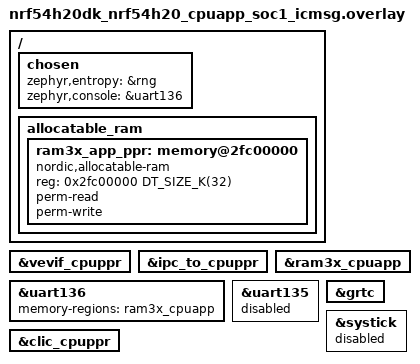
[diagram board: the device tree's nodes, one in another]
/*
 * Copyright (c) 2022 Nordic Semiconductor ASA
 *
 * SPDX-License-Identifier: LicenseRef-Nordic-5-Clause
 */

/ {
	chosen {
		zephyr,entropy = &rng;
		zephyr,console = &uart136;
	};

	allocatable_ram {
		#address-cells = <1>;
		#size-cells = <1>;

		/* Allow to use defined RAM3x region by App and cores owned by
		 * App.
		 */
		ram3x_app_ppr: memory@2fc00000 {
			compatible = "nordic,allocatable-ram";
			reg = <0x2fc00000 DT_SIZE_K(32)>;
			perm-read;
			perm-write;
		};
	};
};

&vevif_cpuppr {
	status = "okay";
};

ipc0: &ipc_to_cpuppr {
	status = "okay";
};

/* ram3x_cpuapp buffer is used by App core UART driver. */
&ram3x_cpuapp {
	status = "okay";
};

&uart136 {
	status = "okay";
	memory-regions = <&ram3x_cpuapp>;
};

&uart135 {
	status = "reserved";
};

&grtc {
	status = "okay";
};

/* Enable PPR clic so App could start PPR. */
&clic_cpuppr {
	status = "okay";
};

/* Disable systick for App core, GRTC is used as tick source. */
&systick {
	status = "disabled";
};
